# AT32UC3L064 device description
Architecture: AVR32_UC3; Family: AVR UC3
Registers are 32-bit, read-write, reset 0x0 unless marked. A register's access mark holds for its fields unless they carry their own. Offsets are from the block's base; [hi:lo] are bit positions; {n}, {i} and the like mark numbered series; 'fields as' and 'values as' point back to an identical list.

## OCD
Instances: OCD 0 in dbgreg
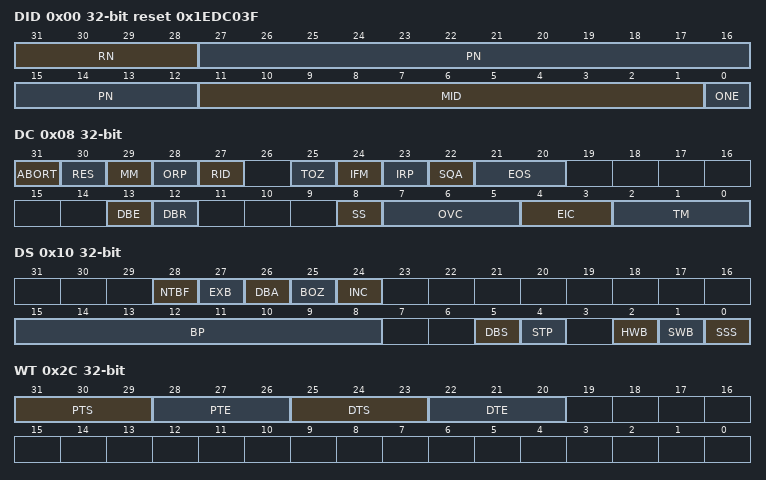
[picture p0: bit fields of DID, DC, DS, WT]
0x00 DID ro reset 0x1EDC03F — The Device ID Register (DID) provides key attributes to the development tool concerning the embedded processor. This is the same as the value returned by the JTAG ID instruction.
  [31:28] RN — Revision Number
  [27:12] PN — Product Number
  [11:1] MID — Manufacturer ID
  [0] ONE — Always reads as 1
0x08 DC — DC is used for basic development control of the CPU.
  [31] ABORT
  [30] RES — Application Reset
  [29] MM — Monitor Mode
  [28] ORP — OCD Register Protect
  [27] RID — Run In Debug
  [25] TOZ — Trap Opcode Zero
  [24] IFM — Ignore First Match
  [23] IRP — Instruction Replace
  [22] SQA — Software Quality Assurance
  [21:20] EOS — Event Out Select
    0=NOP; 1=DEBUG_MODE; 2=BREAKPOINT_WATCHPOINT; 3=THQ
  [13] DBE — Debug Enable
  [12] DBR — Debug Request
  [8] SS — Single Step
  [7:5] OVC — Overrun Control
    0=OVERRUN; 1=DELAY_CPU_BTM; 2=DELAY_CPU_DTM; 3=DELAY_CPU_BTM_DTM
  [4:3] EIC — EVTI Control
    0=PROGRAM_AND_DATA_TRACE; 1=BREAKPOINT; 2=NOP
  [2:0] TM — Trace Mode
0x10 DS ro — This register is used to examine the debug state of the CPU and the cause for entering Debug Mode. Note that multiple sources may trigger Debug Mode simultaneously, causing more than one bit to be set. The register is read only. All bits are dynamic and do not require clearing.
  [28] NTBF — NanoTrace Buffer Full
  [27] EXB — External Breakpoint
  [26] DBA — Debug Acknowledge
  [25] BOZ — Break on Opcode Zero
  [24] INC — Instruction Complete
  [15:8] BP — Breakpoint Status
  [5] DBS — Debug Status
  [4] STP — Stop Status
  [2] HWB — Hardware Breakpoint Status
  [1] SWB — Software Breakpoint Status
  [0] SSS — Single Step Status
0x2C WT
  [31:29] PTS — Program Trace Start
    0=DISABLED; 1=PROGRAM_0B; 2=PROGRAM_1A; 3=PROGRAM_1B; 4=PROGRAM_2A; 5=PROGRAM_2B; 6=DATA_3A; 7=DATA_3B
  [28:26] PTE — Program Trace End
  [25:23] DTS — Data Trace Start
  [22:20] DTE — Data Trace End
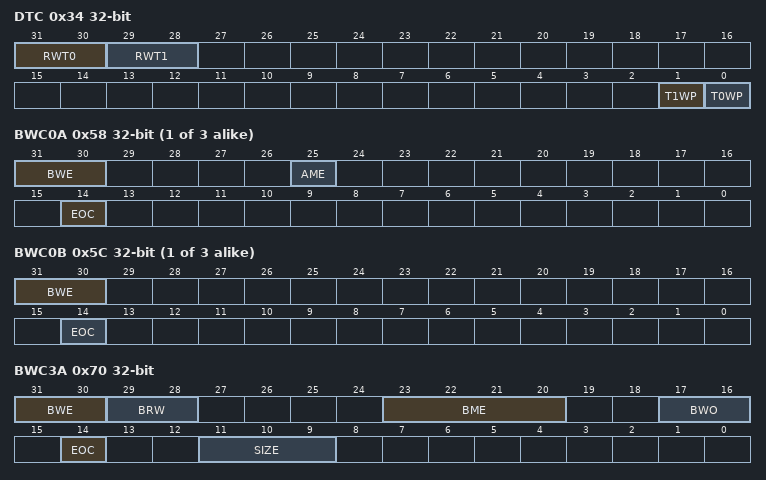
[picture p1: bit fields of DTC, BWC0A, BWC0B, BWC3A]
0x34 DTC — This register controls actions taken on data accesses within all data trace channels.
  [31:30] RWT0 — Read/Write Trace Channel 0
    0=NO_TRACE; 1=DATA_READ; 2=DATA_WRITE; 3=DATA_READ_WRITE
  [29:28] RWT1 — Read/Write Trace Channel 1
    0=NO_TRACE; 1=DATA_READ; 2=DATA_WRITE; 3=DATA_READ_WRITE
  [1] T1WP — Trace Channel 1 Watchpoint
  [0] T0WP — Trace Channel 0 Watchpoint
0x38 DTSA0 — DTSAn and DTEAn define the inclusive data access range [DTSAn : DTEAn] for trace channel n. Each trace channel 0 and 1 has its own DTSA/DTEA register pair. If DTSA=DTEA, the trace channel will match on accesses to a single location. If DTSA>DTEA, no match will occur for the trace channel.
  [31:0] DTSA — Start adress for trace visibility
0x3C DTSA1 — DTSAn and DTEAn define the inclusive data access range [DTSAn : DTEAn] for trace channel n. Each trace channel 0 and 1 has its own DTSA/DTEA register pair. If DTSA=DTEA, the trace channel will match on accesses to a single location. If DTSA>DTEA, no match will occur for the trace channel.
  [31:0] DTSA — Start adress for trace visibility
0x48 DTEA0 — DTSAn and DTEAn define the inclusive data access range [DTSAn : DTEAn] for trace channel n. Each trace channel 0 and 1 has its own DTSA/DTEA register pair. If DTSA=DTEA, the trace channel will match on accesses to a single location. If DTSA>DTEA, no match will occur for the trace channel.
  [31:0] DTEA — End adress for trace visibility
0x4C DTEA1 — DTSAn and DTEAn define the inclusive data access range [DTSAn : DTEAn] for trace channel n. Each trace channel 0 and 1 has its own DTSA/DTEA register pair. If DTSA=DTEA, the trace channel will match on accesses to a single location. If DTSA>DTEA, no match will occur for the trace channel.
  [31:0] DTEA — End adress for trace visibility
{0x58+8i} BWC{i}A (i=0..2)
  [31:30] BWE — Breakpoint/Watchpoint Enable
    0=DISABLED; 1=BREAKPOINT_ENABLED; 3=WATCHPOINT_ENABLED
  [25] AME — Address Mask Enable
  [14] EOC — EVTO Control
{0x5C+8i} BWC{i}B (i=0..2)
  [31:30] BWE — Breakpoint/Watchpoint Enable
    0=DISABLED; 1=BREAKPOINT_ENABLED; 3=WATCHPOINT_ENABLED
  [14] EOC — EVTO Control
0x70 BWC3A
  [31:30] BWE — Breakpoint/Watchpoint Enable
    0=DISABLED; 1=BREAKPOINT_ENABLED; 3=WATCHPOINT_ENABLED
  [29:28] BRW — Breakpoint/Watchpoint Read/Write Select
    0=READ_BREAK; 1=WRITE_BREAK; 2=ANY_ACCES_BREAK
  [23:20] BME — Breakpoint/Watchpoint Data Mask
  [17:16] BWO — Breakpoint/Watchpoint Operand
  [14] EOC — EVTO Control
  [11:9] SIZE — Size bits to match
    4=BYTE_ACCESS; 5=HALFWORD_ACCESS; 6=WORD_ACCESS; 7=DOUBLE_WORD_ACCESS
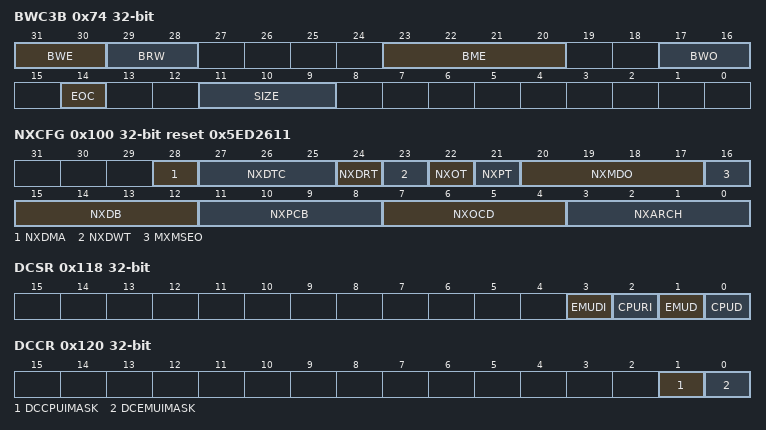
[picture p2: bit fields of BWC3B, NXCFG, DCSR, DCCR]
0x74 BWC3B
  fields as BWC3A
{0x78+8i} BWA{i}A (i=0..2) — The 6 BWA registers contains one instruction address each. The address can be used for a single breakpoint match or used as start and end point of a range.
  [31:0] BWA — Breakpoint/Watchpoint Address
{0x7C+8i} BWA{i}B (i=0..2) — The 6 BWA registers contains one instruction address each. The address can be used for a single breakpoint match or used as start and end point of a range.
  [31:0] BWA — Breakpoint/Watchpoint Address
0x90 BWA3A
  [31:0] BWA — Address of data for breakpoint or watchpoint generation.
0x94 BWA3B
  fields as BWA3A
0x98 BWD3A — Breakpoint/Watchpoint Data 3A
  [31:0] BWD
0x9C BWD3B — Breakpoint/Watchpoint Data 3B
  [31:0] BWD
0x100 NXCFG ro reset 0x5ED2611 — The Nexus Configuration Register (NXCFG) provides key information about the specific implementation of theCPU and OCD architecture, and the configuration of the Nexus development features on this device. This informationis static, and may be used to develop generic Nexus debuggers which will work across a family of AVR-IIdevices with different Nexus configurations.
  [28] NXDMA — Direct Memory Access Support
  [27:25] NXDTC — Data Trace Channels
  [24] NXDRT — Data Read Trace Support
  [23] NXDWT — Data Write Trace Support
  [22] NXOT — Ownership Trace Support
  [21] NXPT — Program Trace Support
  [20:17] NXMDO — AUX MDO Pins
  [16] MXMSEO — AUX MSEO Pins
  [15:12] NXDB — Number of Data breakpoints
  [11:8] NXPCB — Number of PC breakpoints
  [7:4] NXOCD — OCD Version
  [3:0] NXARCH — Architecture
0x104 DINST — The Debug Instruction Register contains the instruction to be executed in OCD Mode. The CPU fetches and executesthe instruction faster than they can be written by the Debug port. DINST is also used to store the instructionto replace the breakpoint instruction.
  [31:0] DINST — Debug Instruction
0x108 DPC — This register contains the PC value of the last executed instruction in any non-debug mode. This allows a debugger to sample program execution addresses for statistical purposes without interrupting the CPU.
0x110 DCCPU — If the CPU wants to transmit data to the debugger tool, it writes data to the Debug Communication CPU Register using mtdr. By writing this register, a dirty bit is set in the Debug Communication Status Register. The emulator should poll the status register and read DCCPU if the dirty bit is set.
  [31:0] DATA — Data value
0x114 DCEMU — When the emulator writes to this register, a dirty bit is set in the Debug Communication Status register. The CPU can poll this bit to see if DCEMU contains unread data.
  [31:0] DATA — Data value
0x118 DCSR — To avoid overruns the CPU must poll this register before writing a new value to DCCPU. Note that the bits in this register are not automatically cleared in OCD mode. This allows a debugger to update views and observe the system without accidentally modifying the DCSR register.
  [3] EMUDI — Emulator Data Dirty interrupt flag
  [2] CPURI — CPU Data read Interrupt flag
  [1] EMUD — Emulator Data Dirty
  [0] CPUD — CPU Data Dirty
0x11C PID — The CPU should write the current Process ID value to this register, whenever the RTOS performs a process switch. This will automatically create an Ownership Trace Message to be transmitted to the tool. This register can be written from any privileged CPU mode.
  [31:0] PROCESS — Process ID
0x120 DCCR — Debug communication control register.
  [1] DCCPUIMASK, [0] DCEMUIMASK
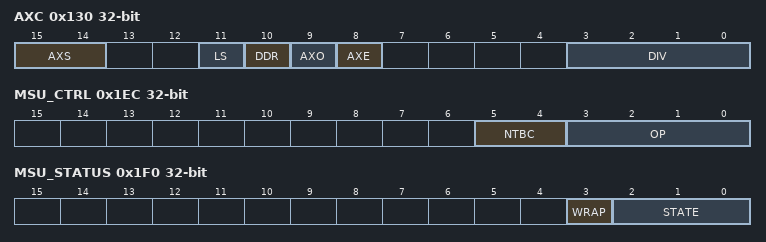
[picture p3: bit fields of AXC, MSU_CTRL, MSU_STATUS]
0x130 AXC — This register allows greater flexibility in controlling the operation of the AUX port than specified by the Nexus standard. This includes enabling the AUX port, and controlling the speed of the clock and data compared to the CPU clock.
  [15:14] AXS — Auxiliary Port Select
  [11] LS — Low Speed
  [10] DDR — Double Data Rate
  [9] AXO — Auxiliary Port Override
  [8] AXE — Auxiliary Port Enable
  [3:0] DIV — Division factor
0x1E0 MSU_ADDRHI reset not defined
  [3:0] ADDRHI
0x1E4 MSU_ADDRLO reset not defined
  [31:2] WADDR
0x1E8 MSU_LENGTH reset not defined
  [31:2] WLEN
0x1EC MSU_CTRL
  [5:4] NTBC
    0=OVER; 1=DISABLE; 2=BREAK_STOP; 3=BREAK_FLUSH
  [3:0] OP
    0=NONE; 1=CRC; 2=NTRACE; 3=MBIST
0x1F0 MSU_STATUS
  [3] WRAP
  [2:0] STATE
    0=DONE; 1=BUSY; 2=NOT_IMPL; 3=BUS_ERR; 4=FAILED; 5=LOCKED; 6=CANCELED
0x1F4 MSU_DATA reset not defined
0x1F8 MSU_TAIL reset not defined
  [31:2] WADDR
